# DA14682 register map
Vendor: Dialog; Series: DA14682; File version: 1.2
CPU: CM0 r1p0, little endian, MPU, FPU, 3 interrupt priority bits
Registers are 16-bit, read-write, reset 0x0 unless marked. A register's access mark holds for its fields unless they carry their own. Offsets are from the block's base; [hi:lo] are bit positions; <NAME> marks a mode.

## GPREG — GPREG registers
Base 0x50003300
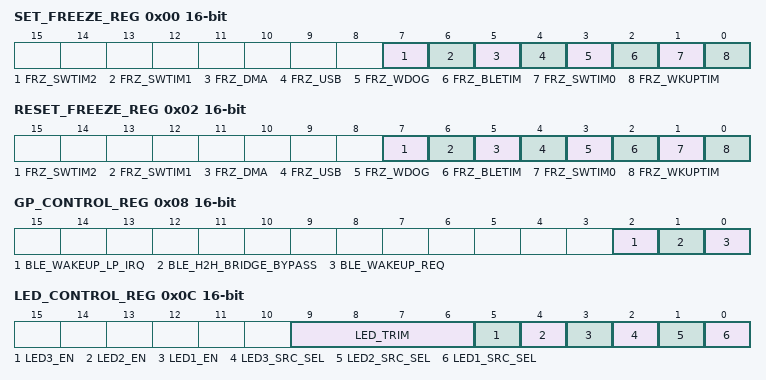
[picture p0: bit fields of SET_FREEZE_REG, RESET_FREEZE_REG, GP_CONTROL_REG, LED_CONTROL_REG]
0x00 SET_FREEZE_REG — Controls freezing of various timers/counters (incl. DMA and USB).
  [7] FRZ_SWTIM2 — If '1', the SW Timer (TIMER2) is frozen, '0' is discarded.
  [6] FRZ_SWTIM1 — If '1', the SW Timer (TIMER1) is frozen, '0' is discarded.
  [5] FRZ_DMA — If '1', the DMA is frozen, '0' is discarded.
  [4] FRZ_USB — If '1', the USB is frozen, '0' is discarded.
  [3] FRZ_WDOG — If '1', the watchdog timer is frozen, '0' is discarded. WATCHDOG_CTRL_REG[NMI_RST] must be '0' to allow the freeze function.
  [2] FRZ_BLETIM — If '1', the BLE master clock is frozen, '0' is discarded.
  [1] FRZ_SWTIM0 — If '1', the SW Timer (TIMER0) is frozen, '0' is discarded.
  [0] FRZ_WKUPTIM — If '1', the Wake Up Timer is frozen, '0' is discarded.
0x02 RESET_FREEZE_REG — Controls unfreezing of various timers/counters (incl. DMA and USB).
  [7] FRZ_SWTIM2 — If '1', the SW Timer (TIMER2) continues, '0' is discarded.
  [6] FRZ_SWTIM1 — If '1', the SW Timer (TIMER1) continues, '0' is discarded.
  [5] FRZ_DMA — If '1', the DMA continues, '0' is discarded.
  [4] FRZ_USB — If '1', the USB continues, '0' is discarded.
  [3] FRZ_WDOG — If '1', the watchdog timer continues, '0' is discarded.
  [2] FRZ_BLETIM — If '1', the BLE master clock continues, '0' is discarded.
  [1] FRZ_SWTIM0 — If '1', the SW Timer (TIMER0) continues, '0' is discarded.
  [0] FRZ_WKUPTIM — If '1', the Wake Up Timer continues, '0' is discarded.
0x04 DEBUG_REG reset 0x1 — Various debug information register.
  [0] DEBUGS_FREEZE_EN — Default '1', freezing of the on-chip timers is enabled when the Cortex-M0 is halted in DEBUG State. If '0', freezing of the on-chip timers is depending on FREEZE_REG when the Cortex-M0 is halted in DEBUG State except the watchdog timer. The watchdog timer is always frozen when the Cortex-M0 is halted in DEBUG State. Note: This bit is retained.
0x06 GP_STATUS_REG — General purpose system status register.
  [0] CAL_PHASE — If '1', it designates that the chip is in Calibration Phase i.e. the OTP has been initially programmed but no Calibration has occured.
0x08 GP_CONTROL_REG — General purpose system control register.
  [2] BLE_WAKEUP_LP_IRQ ro — The current value of the BLE_WAKEUP_LP_IRQ interrupt request.
  [1] BLE_H2H_BRIDGE_BYPASS — If '1', the AHB-to-AHB bridge is bypassed, needed to access the BLE Register file, only when the system clock source is the XTAL and both hclk and ble_hclk are running at 16MHz, i.e. at the XTAL clock rate.
  [0] BLE_WAKEUP_REQ — If '1', the BLE wakes up. Must be kept high at least for 1 low power clock period. If the BLE is in deep sleep state, then by setting this bit it will cause the wakeup LP IRQ to be asserted with a delay of 3 to 4 low power cycles.
0x0A ECC_BASE_ADDR_REG — Base address of the ECC Crypto memory register.
  [6:0] ECC_BASE_ADDR — Contains the base address of the ECC Crypto memory. Memory allocation is in pages of 1KB and up to 127KB. Since the ECC has an address range of 2KB and the total addressable memory range is 128KB, the maximum value of 0x7F (127KB offset) will result in 1KB at the top of the memory range and the other 1KB at the bottom of the memory range.
0x0C LED_CONTROL_REG — Controls muxing and enabling of the LEDs.
  [9:6] LED_TRIM — LED current trimming bits.
  [5] LED3_EN — 0: LED3 disabled, 1: LED3 enabled.
  [4] LED2_EN — 0: LED2 disabled, 1: LED2 enabled.
  [3] LED1_EN — 0: LED1 disabled, 1: LED1 enabled.
  [2] LED3_SRC_SEL — 0: LED3 = PWM4, 1: LED3 = Breathing Timer.
  [1] LED2_SRC_SEL — 0: LED2 = PWM3, 1: LED2 = Breathing Timer.
  [0] LED1_SRC_SEL — 0: LED1 = PWM2, 1: LED1 = Breathing Timer. Note: The PWM2/3/4 can also be routed to GPIOs using PID 25/26/27 respectively.
0x0E BLE_FINECNT_SAMP_REG — BLE FINECNT sampled value while in deep sleep state.
  [9:0] BLE_FINECNT_SAMP — This register is located at the Always On Power Domain and it holds the automatically sampled value of the BLE FINECNT timer The HW automatically samples the value into this register during the sequence of "BLE Sleep On" and restores automatically the value during the BLE Wake up sequence. The Software may read and modify the value while the BLE is in Sleep state. While the BLE is awake, the value of the register has no meaning, while changing the value by writing another one will have no effect in the operation of the BLE core.
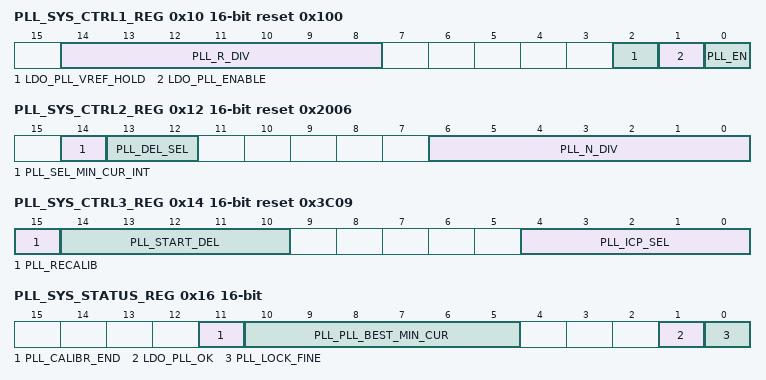
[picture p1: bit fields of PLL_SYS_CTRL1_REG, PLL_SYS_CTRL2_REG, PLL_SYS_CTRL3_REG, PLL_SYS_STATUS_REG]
0x10 PLL_SYS_CTRL1_REG reset 0x100 — System PLL control register 1.
  [14:8] PLL_R_DIV — PLL Output dvider R (x means divide by x, 0 means divide by 1)
  [2] LDO_PLL_VREF_HOLD — 0: indicates that the reference input is tracked, 1: indicates that the reference input is sampled.
  [1] LDO_PLL_ENABLE — 0: LDO PLL off, 1: LDO PLL on.
  [0] PLL_EN — 0: Power down 1: PLL on
0x12 PLL_SYS_CTRL2_REG reset 0x2006 — System PLL control register 2.
  [14] PLL_SEL_MIN_CUR_INT — 0: VCO current read from min_current <5:0>, 1: VCO current is internally determined with a calibration algoritm.
  [13:12] PLL_DEL_SEL — PLL manual delay value for Phase Frequency Detector. 0: 0.493 1: 0.814 2: 1.13 ns <- default 3: 1.44 ns
  [6:0] PLL_N_DIV — PLL Loop divider N (x means divide by x, 0 means divide by 1)
0x14 PLL_SYS_CTRL3_REG reset 0x3C09 — System PLL control register 3.
  [15] PLL_RECALIB — Recalibrate
  [14:10] PLL_START_DEL — Programmable delay time for the loop filter voltage preset value. After PLL_EN is set, the loopfilter precharge resistors are disabled after this delay time. One LSB is 48 ns
  [4:0] PLL_ICP_SEL — PLL charge pump current select One LSB is 5uA.
0x16 PLL_SYS_STATUS_REG — System PLL status register.
  [11] PLL_CALIBR_END ro — Indicates that calibration has finished.
  [10:5] PLL_PLL_BEST_MIN_CUR ro — Calibrated VCO frequency band.
  [1] LDO_PLL_OK ro — 1: Indicates that LDO PLL is in regulation.
  [0] PLL_LOCK_FINE ro — 1: PLL locked
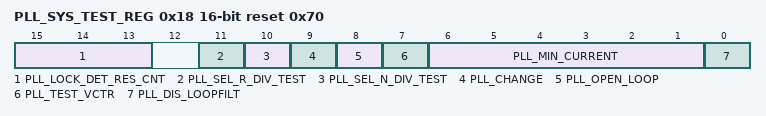
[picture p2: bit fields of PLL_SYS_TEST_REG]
0x18 PLL_SYS_TEST_REG reset 0x70 — System PLL test register.
  [15:13] PLL_LOCK_DET_RES_CNT — Lock measurement time in <tbd> clock cycle of xx usec. After this period PLL_LOCK_FINE is calculated based on the difference of the M and N counted pulses in that period. If PLL_LOCK_FINE is still 0, the lock state machine restarts until PLL_LOCK_FINE gets 1 0: <tbd> usec 7: <tbd> usec
  [11] PLL_SEL_R_DIV_TEST — Select test mode for output divider R Maps PLL_R_DIV input on pins <tbd> and divider output on pin <tbd>
  [10] PLL_SEL_N_DIV_TEST — Select test mode for loop divider N. Maps PLL_N_DIV input on pins <tbd> and divider output on pin <tbd>
  [9] PLL_CHANGE — 0: normal value 1: reverse charge pump up/down signals
  [8] PLL_OPEN_LOOP — 1: set to open loop to termine max frequency
  [7] PLL_TEST_VCTR — 1: map loopfilter voltage on external pin <tbd>
  [6:1] PLL_MIN_CURRENT — VCO current trimming.
  [0] PLL_DIS_LOOPFILT — 1: disable PLL internal loop filter
